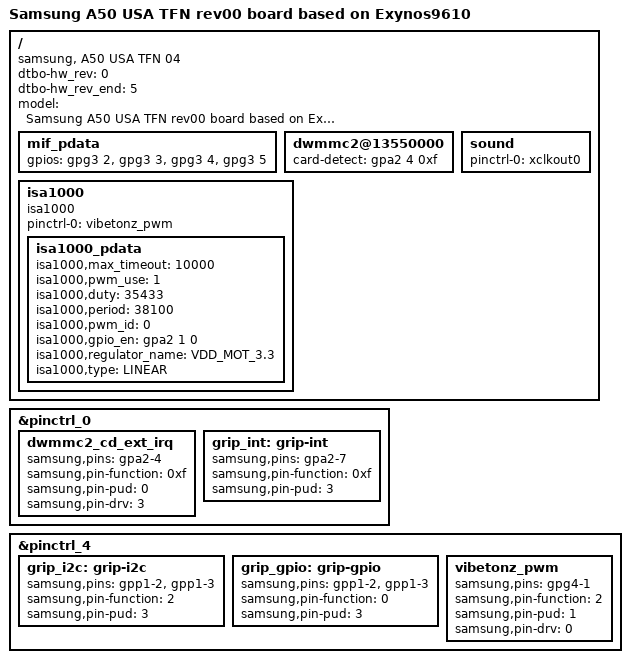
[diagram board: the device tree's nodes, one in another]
/*
 * SAMSUNG EXYNOS9610 board device tree source
 *
 * Copyright (c) 2018 Samsung Electronics Co., Ltd.
 *		http://www.samsung.com
 *
 * This program is free software; you can redistribute it and/or modify
 * it under the terms of the GNU General Public License version 2 as
 * published by the Free Software Foundation.
 */

/dts-v1/;
/plugin/;
#include "exynos9610-a50_common.dtsi"
#include "battery_data_a50_usa_single.dtsi"
#include "exynos9610-a50_fingerprint_04.dtsi"
#include "exynos9610-a50_sensorhub_00.dtsi"
#include "exynos9610-a50_nfc_01.dtsi"
#include "exynos9610-a50_usa_tfn_gpio_04.dtsi"

/ {
	compatible = "samsung, A50 USA TFN 04", "samsung,EXYNOS9610";
	dtbo-hw_rev = <0>;
	dtbo-hw_rev_end = <5>;

	fragment@model {
		target-path = "/";
		__overlay__ {
			#address-cells = <2>;
			#size-cells = <1>;

			model = "Samsung A50 USA TFN rev00 board based on Exynos9610";

			mif_pdata {
				/* GPIOs for HW REV */
				/* XGPIO26-AP_REV0, XGPIO27-AP_REV1, XGPIO28-AP_REV2, XGPIO29-AP_REV3 */
				gpios = <&gpg3 2 0>, <&gpg3 3 0>, <&gpg3 4 0>, <&gpg3 5 0>;
				pinctrl-names = "default";
			};

			dwmmc2@13550000 {
				card-detect = <&gpa2 4 0xf>;
			};			

			isa1000 {
				compatible = "isa1000";
				pinctrl-names = "default";
				pinctrl-0 = <&vibetonz_pwm>;
				isa1000_pdata {
					status = "okay";
					isa1000,max_timeout = <10000>;
					isa1000,pwm_use = <1>;
					isa1000,duty = <35433>;
					isa1000,period = <38100>;
					isa1000,pwm_id = <0>;
					isa1000,gpio_en = <&gpa2 1 0>;
					isa1000,regulator_name = "VDD_MOT_3.3";
					isa1000,type = "LINEAR";
				};
			};

		}; /* end of __overlay__ */
	}; /* end of fragment */

	fragment@sound {
		target-path = "/";
		__overlay__ {
			sound {
				pinctrl-0 = <&xclkout0>;
			};

		}; /* end of __overlay__ */
	}; /* end of fragment */
}; /* end of root */

&pinctrl_0 {
	dwmmc2_cd_ext_irq: dwmmc2_cd_ext_irq {
		samsung,pins = "gpa2-4";
		samsung,pin-function = <0xf>;
		samsung,pin-pud = <0>;
		samsung,pin-drv = <3>;
	};

	grip_int: grip-int {
		samsung,pins = "gpa2-7";
		samsung,pin-function = <0xf>;
		samsung,pin-pud = <3>;
	};	
};

&pinctrl_4 {
	grip_i2c: grip-i2c {
		samsung,pins = "gpp1-2", "gpp1-3";
		samsung,pin-function = <2>;
		samsung,pin-pud = <3>;
	};

	grip_gpio: grip-gpio {
		samsung,pins = "gpp1-2", "gpp1-3";
		samsung,pin-function = <0>;
		samsung,pin-pud = <3>;
	};	
	
	vibetonz_pwm: vibetonz_pwm {
		samsung,pins = "gpg4-1";
		samsung,pin-function = <2>;
		samsung,pin-pud = <1>;
		samsung,pin-drv = <0>;
	};
};
